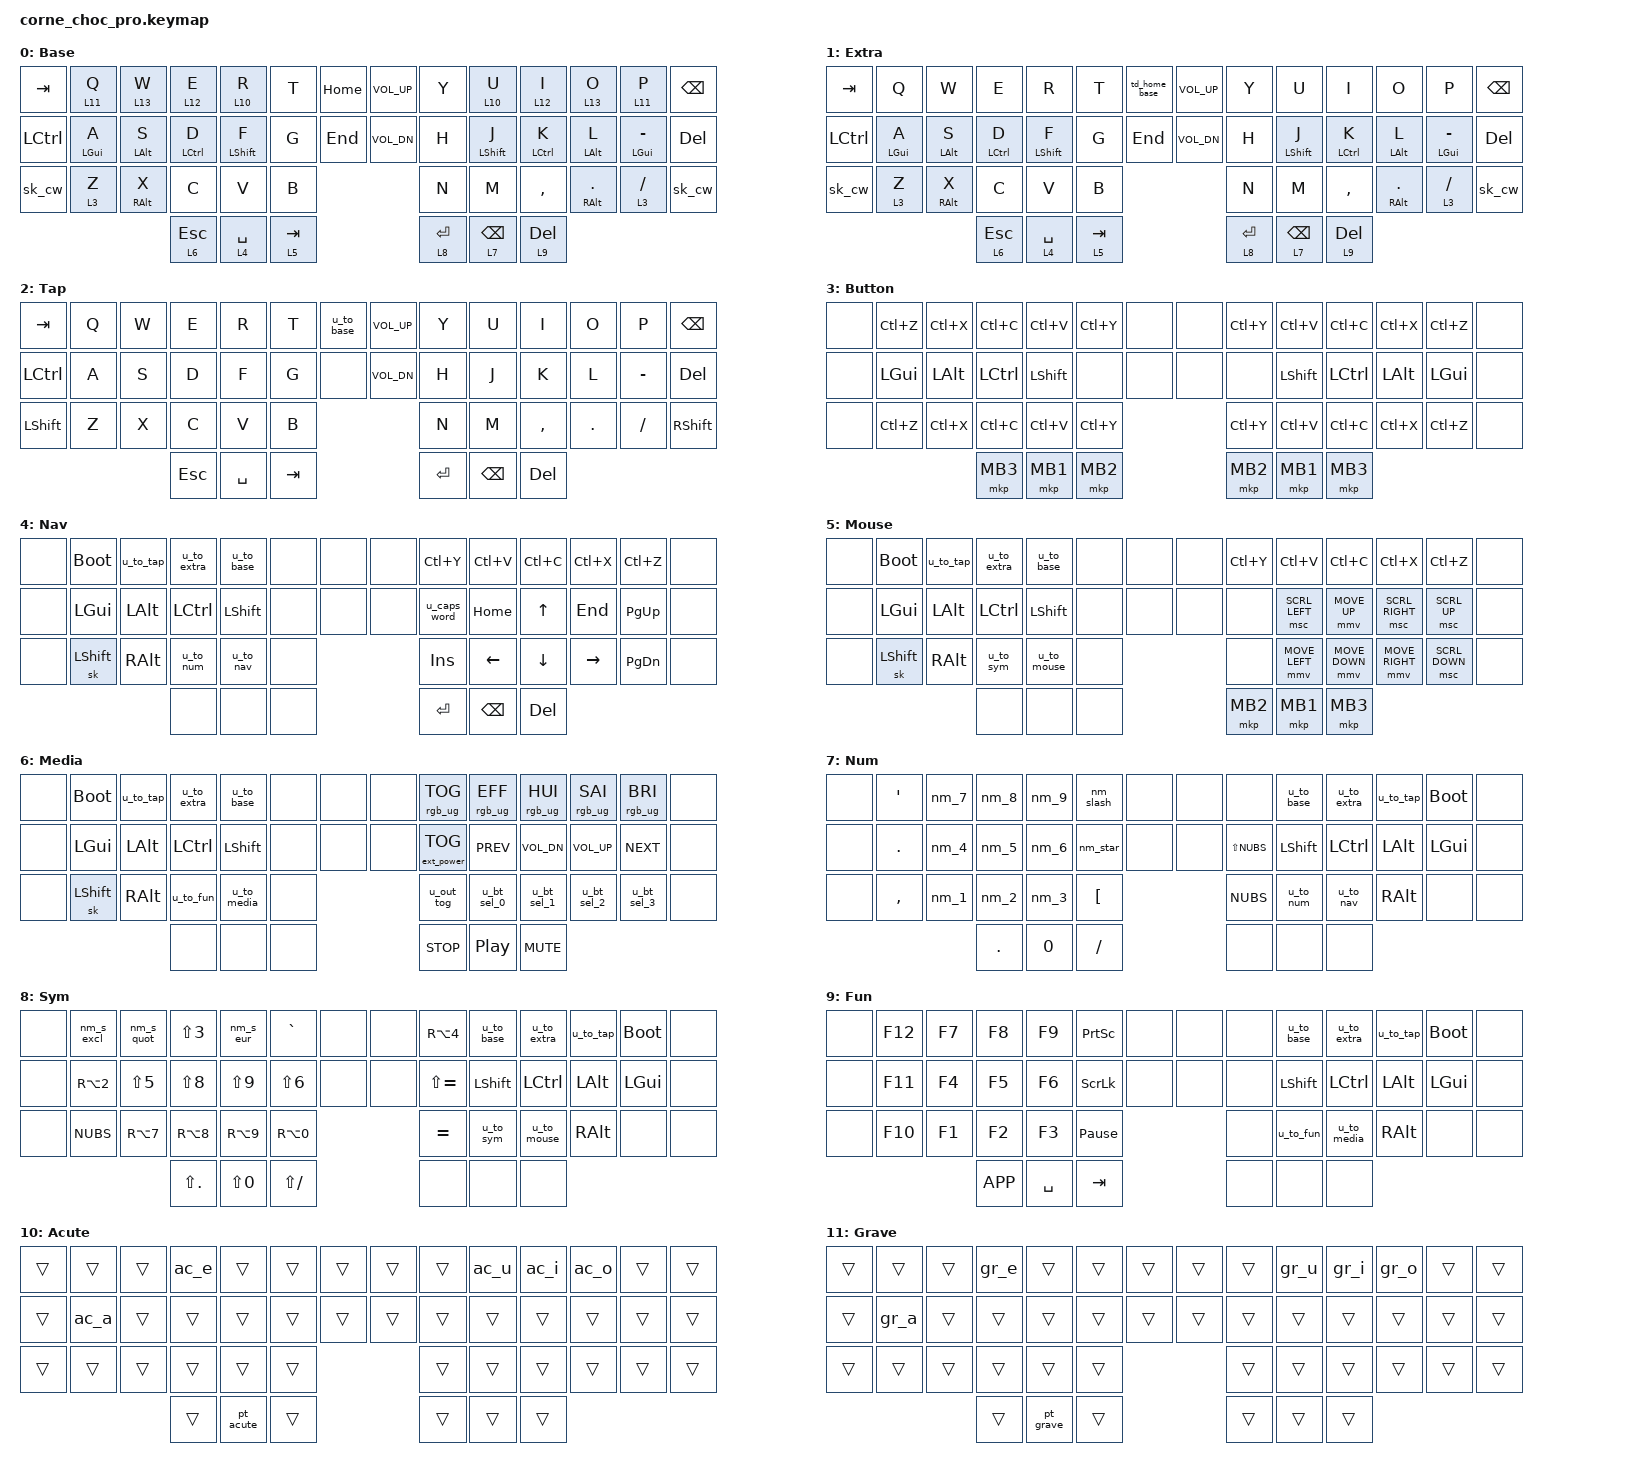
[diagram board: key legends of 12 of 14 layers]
/*
 * Miryoku layout for the Keebart Corne Choc Pro BT (42 keys + 4 centre keys).
 *
 * Expanded by hand from Keebart/miryoku_zmk (manna-harbour/miryoku_zmk) so the
 * ZMK Keymap Editor can read and edit it: every layer is written out as plain
 * bindings and Miryoku's behaviours are plain devicetree nodes, no C-preprocessor
 * layer macros.
 *
 * Options used: alphas = QWERTY, tap layer = QWERTY, extra layer = QWERTY,
 * everything else Miryoku default (home-row navigation on the right hand,
 * Num / Sym / Fun on the left, CUA clipboard keys, no flipped layers).
 *
 * Layer order: 0 Base, 1 Extra, 2 Tap, 3 Button, 4 Nav, 5 Mouse, 6 Media,
 *              7 Num, 8 Sym, 9 Fun, 10 Acute, 11 Grave, 12 Tilde, 13 Circ.
 *              Layer numbers are used in the bindings.
 *
 * Miryoku uses the 36 core keys; the 4 centre keys are &none and free for your
 * own bindings.
 *
 * PORTUGUESE (PORTUGAL) LAYOUT: every character on the Num and Sym layers is sent
 * as the key sequence that prints it on the Windows Portuguese layout (AltGr for
 * [ ] { } @ EUR, Shift for ! " # $ % & ( ) = : ; _ ?, dead key + Space for ` ^ ~ ´ ¨).
 * On the alpha layers the bottom-right key is the physical Portuguese key: -
 * (Shift _); the right pinky sends ' (Shift ?).
 *
 * NUM (hold Backspace): numpad block 7 8 9 / 4 5 6 / 1 2 3, with . , º on the pinky
 * column, / * + on the extra index column, 0 and - on the thumbs, > < on the right
 * hand.  Shift gives the small character of each key: 7 ^  8 ~  9 ´  / `  * ¨  4 %
 * 5 (  6 )  1 EUR  2 $  3 £  . :  , ;  0 =  - _  º ª.
 * SYM (hold Enter): rows  ! " # EUR backslash / @ % ( ) & / < { [ ] }, thumbs : = _ ,
 * § » « on the right hand (Y H N).  Shift: ! ?  " '  EUR $  backslash |  < >.
 * NAV / MOUSE: inverted-T cluster on the right hand (Home Up End PgUp / Left Down
 * Right PgDn, and Scroll L / Mouse Up / Scroll R / Scroll Up / Mouse L, D, R /
 * Scroll Down); the left-hand bottom pinky key is a one-shot Shift (also on Media).
 *
 * CENTRE KEYS (Base and Extra): left pair = Home / End, right pair = Volume Up / Volume Down.
 *
 * OUTER COLUMNS (Base and Extra):  Tab / Ctrl / Shift  |  Backspace / Del / Shift.
 * Shift is one-shot (tap, then the next key is capital); tap it again while it
 * is active for Caps Word; hold it for normal Shift.  The Tap (gaming) layer has
 * plain Shift keys.
 *
 * ACCENTS (Windows, Portuguese (Portugal) keyboard layout)
 * Hold a top-row key on the Base layer and tap a vowel to get an accented one:
 *     hold R or U  + vowel -> acute      (a e i o u)
 *     hold E or I  + vowel -> tilde      (a o, and n for ñ)
 *     hold W or O  + vowel -> circumflex (a e i o u)
 *     hold Q or P  + vowel -> grave      (a e i o u)
 *     tap C + V together   -> Ç          (Shift gives Ç)
 * They send the dead key of the PT-PT layout, then the vowel; Shift is handled so
 * capital letters work.  The Extra layer is plain Miryoku QWERTY without accents.
 * Dead keys used (physical keys): acute = key right of "+", tilde = key left of
 * Enter, grave / circumflex = the same keys with Shift, Ç = key right of "L".
 */

/* Miryoku mouse tuning; must come before pointing.h (its defaults are #ifndef) */
#define ZMK_POINTING_DEFAULT_MOVE_VAL 1250
#define ZMK_POINTING_DEFAULT_SCRL_VAL 100

#include <behaviors.dtsi>
#include <behaviors/mouse_keys.dtsi>
#include <dt-bindings/zmk/keys.h>
#include <dt-bindings/zmk/bt.h>
#include <dt-bindings/zmk/rgb.h>
#include <dt-bindings/zmk/outputs.h>
#include <dt-bindings/zmk/ext_power.h>
#include <dt-bindings/zmk/pointing.h>

/ {
    chosen {
        zmk,physical-layout = &default_layout;
    };
};
/ {
    keymap {
        compatible = "zmk,keymap";

        base_layer {
            display-name = "Base";
            bindings = <
                &kp TAB   &acc_lt 11 Q &acc_lt 13 W &acc_lt 12 E  &acc_lt 10 R  &kp T       &kp HOME &kp C_VOL_UP &kp Y       &acc_lt 10 U  &acc_lt 12 I  &acc_lt 13 O   &acc_lt 11 P     &kp BSPC
                &kp LCTRL &u_mt LGUI A &u_mt LALT S &u_mt LCTRL D &u_mt LSHFT F &kp G       &kp END  &kp C_VOL_DN &kp H       &u_mt LSHFT J &u_mt LCTRL K &u_mt LALT L   &u_mt LGUI MINUS &kp DEL
                &sk_cw    &u_lt 3 Z    &u_mt RALT X &kp C         &kp V         &kp B                             &kp N       &kp M         &kp COMMA     &u_mt RALT DOT &u_lt 3 SLASH    &sk_cw
                                                    &u_lt 6 ESC   &u_lt 4 SPACE &u_lt 5 TAB                       &u_lt 8 RET &u_lt 7 BSPC  &u_lt 9 DEL
            >;
        };

        extra_layer {
            display-name = "Extra";
            bindings = <
                &kp TAB   &kp Q        &kp W        &kp E         &kp R         &kp T       &td_home_base &kp C_VOL_UP &kp Y       &kp U         &kp I         &kp O          &kp P            &kp BSPC
                &kp LCTRL &u_mt LGUI A &u_mt LALT S &u_mt LCTRL D &u_mt LSHFT F &kp G       &kp END       &kp C_VOL_DN &kp H       &u_mt LSHFT J &u_mt LCTRL K &u_mt LALT L   &u_mt LGUI MINUS &kp DEL
                &sk_cw    &u_lt 3 Z    &u_mt RALT X &kp C         &kp V         &kp B                                  &kp N       &kp M         &kp COMMA     &u_mt RALT DOT &u_lt 3 SLASH    &sk_cw
                                                    &u_lt 6 ESC   &u_lt 4 SPACE &u_lt 5 TAB                            &u_lt 8 RET &u_lt 7 BSPC  &u_lt 9 DEL
            >;
        };

        tap_layer {
            display-name = "Tap";
            bindings = <
                &kp TAB   &kp Q &kp W &kp E   &kp R     &kp T   &u_to_base &kp C_VOL_UP &kp Y   &kp U    &kp I     &kp O   &kp P     &kp BSPC
                &kp LCTRL &kp A &kp S &kp D   &kp F     &kp G   &none      &kp C_VOL_DN &kp H   &kp J    &kp K     &kp L   &kp MINUS &kp DEL
                &kp LSHFT &kp Z &kp X &kp C   &kp V     &kp B                           &kp N   &kp M    &kp COMMA &kp DOT &kp SLASH &kp RSHFT
                                      &kp ESC &kp SPACE &kp TAB                         &kp RET &kp BSPC &kp DEL
            >;
        };

        button_layer {
            display-name = "Button";
            bindings = <
                &none &kp LC(Z) &kp LC(X) &kp LC(C) &kp LC(V) &kp LC(Y) &none &none &kp LC(Y) &kp LC(V) &kp LC(C) &kp LC(X) &kp LC(Z) &none
                &none &kp LGUI  &kp LALT  &kp LCTRL &kp LSHFT &none     &none &none &none     &kp LSHFT &kp LCTRL &kp LALT  &kp LGUI  &none
                &none &kp LC(Z) &kp LC(X) &kp LC(C) &kp LC(V) &kp LC(Y)             &kp LC(Y) &kp LC(V) &kp LC(C) &kp LC(X) &kp LC(Z) &none
                                          &mkp MB3  &mkp MB1  &mkp MB2              &mkp MB2  &mkp MB1  &mkp MB3
            >;
        };

        nav_layer {
            display-name = "Nav";
            bindings = <
                &none &bootloader &u_to_tap &u_to_extra &u_to_base &none &none &none &kp LC(Y)    &kp LC(V) &kp LC(C) &kp LC(X) &kp LC(Z) &none
                &none &kp LGUI    &kp LALT  &kp LCTRL   &kp LSHFT  &none &none &none &u_caps_word &kp HOME  &kp UP    &kp END   &kp PG_UP &none
                &none &sk LSHFT   &kp RALT  &u_to_num   &u_to_nav  &none             &kp INS      &kp LEFT  &kp DOWN  &kp RIGHT &kp PG_DN &none
                                            &none       &none      &none             &kp RET      &kp BSPC  &kp DEL
            >;
        };

        mouse_layer {
            display-name = "Mouse";
            bindings = <
                &none &bootloader &u_to_tap &u_to_extra &u_to_base  &none &none &none &kp LC(Y) &kp LC(V)      &kp LC(C)      &kp LC(X)       &kp LC(Z)      &none
                &none &kp LGUI    &kp LALT  &kp LCTRL   &kp LSHFT   &none &none &none &none     &msc SCRL_LEFT &mmv MOVE_UP   &msc SCRL_RIGHT &msc SCRL_UP   &none
                &none &sk LSHFT   &kp RALT  &u_to_sym   &u_to_mouse &none             &none     &mmv MOVE_LEFT &mmv MOVE_DOWN &mmv MOVE_RIGHT &msc SCRL_DOWN &none
                                            &none       &none       &none             &mkp MB2  &mkp MB1       &mkp MB3
            >;
        };

        media_layer {
            display-name = "Media";
            bindings = <
                &none &bootloader &u_to_tap &u_to_extra &u_to_base  &none &none &none &rgb_ug RGB_TOG   &rgb_ug RGB_EFF &rgb_ug RGB_HUI &rgb_ug RGB_SAI &rgb_ug RGB_BRI &none
                &none &kp LGUI    &kp LALT  &kp LCTRL   &kp LSHFT   &none &none &none &ext_power EP_TOG &kp C_PREV      &kp C_VOL_DN    &kp C_VOL_UP    &kp C_NEXT      &none
                &none &sk LSHFT   &kp RALT  &u_to_fun   &u_to_media &none             &u_out_tog        &u_bt_sel_0     &u_bt_sel_1     &u_bt_sel_2     &u_bt_sel_3     &none
                                            &none       &none       &none             &kp C_STOP        &kp C_PP        &kp C_MUTE
            >;
        };

        num_layer {
            display-name = "Num";
            bindings = <
                &none &kp SQT   &nm_7 &nm_8   &nm_9  &nm_slash &none &none &none        &u_to_base &u_to_extra &u_to_tap &bootloader &none
                &none &kp DOT   &nm_4 &nm_5   &nm_6  &nm_star  &none &none &kp LS(NUBS) &kp LSHFT  &kp LCTRL   &kp LALT  &kp LGUI    &none
                &none &kp COMMA &nm_1 &nm_2   &nm_3  &kp LBKT              &kp NUBS     &u_to_num  &u_to_nav   &kp RALT  &none       &none
                                      &kp DOT &kp N0 &kp SLASH             &none        &none      &none
            >;
        };

        sym_layer {
            display-name = "Sym";
            bindings = <
                &none &nm_s_excl &nm_s_quot &kp LS(N3)  &nm_s_eur  &kp GRAVE     &none &none &kp RA(N4)    &u_to_base &u_to_extra &u_to_tap &bootloader &none
                &none &kp RA(N2) &kp LS(N5) &kp LS(N8)  &kp LS(N9) &kp LS(N6)    &none &none &kp LS(EQUAL) &kp LSHFT  &kp LCTRL   &kp LALT  &kp LGUI    &none
                &none &kp NUBS   &kp RA(N7) &kp RA(N8)  &kp RA(N9) &kp RA(N0)                &kp EQUAL     &u_to_sym  &u_to_mouse &kp RALT  &none       &none
                                            &kp LS(DOT) &kp LS(N0) &kp LS(SLASH)             &none         &none      &none
            >;
        };

        fun_layer {
            display-name = "Fun";
            bindings = <
                &none &kp F12 &kp F7 &kp F8    &kp F9    &kp PSCRN       &none &none &none &u_to_base &u_to_extra &u_to_tap &bootloader &none
                &none &kp F11 &kp F4 &kp F5    &kp F6    &kp SLCK        &none &none &none &kp LSHFT  &kp LCTRL   &kp LALT  &kp LGUI    &none
                &none &kp F10 &kp F1 &kp F2    &kp F3    &kp PAUSE_BREAK             &none &u_to_fun  &u_to_media &kp RALT  &none       &none
                                     &kp K_APP &kp SPACE &kp TAB                     &none &none      &none
            >;
        };

        acute_layer {
            display-name = "Acute";
            bindings = <
                &trans &trans &trans &ac_e  &trans    &trans &trans &trans &trans &ac_u  &ac_i  &ac_o  &trans &trans
                &trans &ac_a  &trans &trans &trans    &trans &trans &trans &trans &trans &trans &trans &trans &trans
                &trans &trans &trans &trans &trans    &trans               &trans &trans &trans &trans &trans &trans
                                     &trans &pt_acute &trans               &trans &trans &trans
            >;
        };

        grave_layer {
            display-name = "Grave";
            bindings = <
                &trans &trans &trans &gr_e  &trans    &trans &trans &trans &trans &gr_u  &gr_i  &gr_o  &trans &trans
                &trans &gr_a  &trans &trans &trans    &trans &trans &trans &trans &trans &trans &trans &trans &trans
                &trans &trans &trans &trans &trans    &trans               &trans &trans &trans &trans &trans &trans
                                     &trans &pt_grave &trans               &trans &trans &trans
            >;
        };

        tilde_layer {
            display-name = "Tilde";
            bindings = <
                &trans &trans &trans &trans &trans    &trans &trans &trans &trans &trans &trans &ti_o  &trans &trans
                &trans &ti_a  &trans &trans &trans    &trans &trans &trans &trans &trans &trans &trans &trans &trans
                &trans &trans &trans &trans &trans    &trans               &ti_n  &trans &trans &trans &trans &trans
                                     &trans &pt_tilde &trans               &trans &trans &trans
            >;
        };

        circ_layer {
            display-name = "Circ";
            bindings = <
                &trans &trans &trans &ci_e  &trans    &trans &trans &trans &trans &ci_u  &ci_i  &ci_o  &trans &trans
                &trans &ci_a  &trans &trans &trans    &trans &trans &trans &trans &trans &trans &trans &trans &trans
                &trans &trans &trans &trans &trans    &trans               &trans &trans &trans &trans &trans &trans
                                     &trans &pt_caret &trans               &trans &trans &trans
            >;
        };
    };
};

/* ---- Miryoku behaviours ------------------------------------------------- */

/ {
    behaviors {
        /* home-row mod-tap: &u_mt <modifier> <key> */
        u_mt: u_mt {
            compatible = "zmk,behavior-hold-tap";
            #binding-cells = <2>;
            tapping-term-ms = <200>;
            flavor = "tap-preferred";
            bindings = <&kp>, <&kp>;
        };

        /* layer-tap: &u_lt <layer> <key> */
        u_lt: u_lt {
            compatible = "zmk,behavior-hold-tap";
            #binding-cells = <2>;
            tapping-term-ms = <200>;
            flavor = "tap-preferred";
            bindings = <&mo>, <&kp>;
        };

        /* accent layer-tap: &acc_lt <layer> <key>.  Same timing as Miryoku's
           home-row keys; quick-tap keeps repeated letters and key repeat working */
        acc_lt: acc_lt {
            compatible = "zmk,behavior-hold-tap";
            #binding-cells = <2>;
            tapping-term-ms = <200>;
            quick-tap-ms = <175>;
            flavor = "tap-preferred";
            bindings = <&mo>, <&kp>;
        };

        /* double-tap guards: a single tap does nothing, a double tap switches layer */
        u_to_base: u_to_base {
            compatible = "zmk,behavior-tap-dance";
            #binding-cells = <0>;
            tapping-term-ms = <200>;
            bindings = <&none>, <&to 0>;
        };
        u_to_extra: u_to_extra {
            compatible = "zmk,behavior-tap-dance";
            #binding-cells = <0>;
            tapping-term-ms = <200>;
            bindings = <&none>, <&to 1>;
        };
        u_to_tap: u_to_tap {
            compatible = "zmk,behavior-tap-dance";
            #binding-cells = <0>;
            tapping-term-ms = <200>;
            bindings = <&none>, <&to 2>;
        };
        u_to_button: u_to_button {
            compatible = "zmk,behavior-tap-dance";
            #binding-cells = <0>;
            tapping-term-ms = <200>;
            bindings = <&none>, <&to 3>;
        };
        u_to_nav: u_to_nav {
            compatible = "zmk,behavior-tap-dance";
            #binding-cells = <0>;
            tapping-term-ms = <200>;
            bindings = <&none>, <&to 4>;
        };
        u_to_mouse: u_to_mouse {
            compatible = "zmk,behavior-tap-dance";
            #binding-cells = <0>;
            tapping-term-ms = <200>;
            bindings = <&none>, <&to 5>;
        };
        u_to_media: u_to_media {
            compatible = "zmk,behavior-tap-dance";
            #binding-cells = <0>;
            tapping-term-ms = <200>;
            bindings = <&none>, <&to 6>;
        };
        u_to_num: u_to_num {
            compatible = "zmk,behavior-tap-dance";
            #binding-cells = <0>;
            tapping-term-ms = <200>;
            bindings = <&none>, <&to 7>;
        };
        u_to_sym: u_to_sym {
            compatible = "zmk,behavior-tap-dance";
            #binding-cells = <0>;
            tapping-term-ms = <200>;
            bindings = <&none>, <&to 8>;
        };
        u_to_fun: u_to_fun {
            compatible = "zmk,behavior-tap-dance";
            #binding-cells = <0>;
            tapping-term-ms = <200>;
            bindings = <&none>, <&to 9>;
        };
        /* Extra layer, top-left centre: tap = Home, double-tap = back to Base */
        td_home_base: td_home_base {
            compatible = "zmk,behavior-tap-dance";
            #binding-cells = <0>;
            tapping-term-ms = <200>;
            bindings = <&kp HOME>, <&to 0>;
        };

        /* shift = alternate function */
        u_bt_sel_0: u_bt_sel_0 {
            compatible = "zmk,behavior-mod-morph";
            #binding-cells = <0>;
            bindings = <&bt BT_SEL 0>, <&u_bt_sel_0_clr>;
            mods = <(MOD_LSFT|MOD_RSFT)>;
        };
        u_bt_sel_1: u_bt_sel_1 {
            compatible = "zmk,behavior-mod-morph";
            #binding-cells = <0>;
            bindings = <&bt BT_SEL 1>, <&u_bt_sel_1_clr>;
            mods = <(MOD_LSFT|MOD_RSFT)>;
        };
        u_bt_sel_2: u_bt_sel_2 {
            compatible = "zmk,behavior-mod-morph";
            #binding-cells = <0>;
            bindings = <&bt BT_SEL 2>, <&u_bt_sel_2_clr>;
            mods = <(MOD_LSFT|MOD_RSFT)>;
        };
        u_bt_sel_3: u_bt_sel_3 {
            compatible = "zmk,behavior-mod-morph";
            #binding-cells = <0>;
            bindings = <&bt BT_SEL 3>, <&u_bt_sel_3_clr>;
            mods = <(MOD_LSFT|MOD_RSFT)>;
        };
        u_out_tog: u_out_tog {
            compatible = "zmk,behavior-mod-morph";
            #binding-cells = <0>;
            bindings = <&out OUT_TOG>, <&out OUT_USB>;
            mods = <(MOD_LSFT|MOD_RSFT)>;
        };
        u_caps_word: u_caps_word {
            compatible = "zmk,behavior-mod-morph";
            #binding-cells = <0>;
            bindings = <&caps_word>, <&kp CAPS>;
            mods = <(MOD_LSFT|MOD_RSFT)>;
        };

        /* Shift: tap = one-shot Shift, tap again (while it is active) = Caps Word,
           hold = normal Shift */
        sk_cw: sk_cw {
            compatible = "zmk,behavior-mod-morph";
            #binding-cells = <0>;
            bindings = <&sk LSHFT>, <&caps_word>;
            mods = <(MOD_LSFT|MOD_RSFT)>;
        };

        /* accented vowels: Shift held = capital letter */
        ac_a: ac_a {
            compatible = "zmk,behavior-mod-morph";
            #binding-cells = <0>;
            bindings = <&ac_a_l>, <&ac_a_u>;
            mods = <(MOD_LSFT|MOD_RSFT)>;
        };
        ac_e: ac_e {
            compatible = "zmk,behavior-mod-morph";
            #binding-cells = <0>;
            bindings = <&ac_e_l>, <&ac_e_u>;
            mods = <(MOD_LSFT|MOD_RSFT)>;
        };
        ac_i: ac_i {
            compatible = "zmk,behavior-mod-morph";
            #binding-cells = <0>;
            bindings = <&ac_i_l>, <&ac_i_u>;
            mods = <(MOD_LSFT|MOD_RSFT)>;
        };
        ac_o: ac_o {
            compatible = "zmk,behavior-mod-morph";
            #binding-cells = <0>;
            bindings = <&ac_o_l>, <&ac_o_u>;
            mods = <(MOD_LSFT|MOD_RSFT)>;
        };
        ac_u: ac_u {
            compatible = "zmk,behavior-mod-morph";
            #binding-cells = <0>;
            bindings = <&ac_u_l>, <&ac_u_u>;
            mods = <(MOD_LSFT|MOD_RSFT)>;
        };
        gr_a: gr_a {
            compatible = "zmk,behavior-mod-morph";
            #binding-cells = <0>;
            bindings = <&gr_a_l>, <&gr_a_u>;
            mods = <(MOD_LSFT|MOD_RSFT)>;
        };
        gr_e: gr_e {
            compatible = "zmk,behavior-mod-morph";
            #binding-cells = <0>;
            bindings = <&gr_e_l>, <&gr_e_u>;
            mods = <(MOD_LSFT|MOD_RSFT)>;
        };
        gr_i: gr_i {
            compatible = "zmk,behavior-mod-morph";
            #binding-cells = <0>;
            bindings = <&gr_i_l>, <&gr_i_u>;
            mods = <(MOD_LSFT|MOD_RSFT)>;
        };
        gr_o: gr_o {
            compatible = "zmk,behavior-mod-morph";
            #binding-cells = <0>;
            bindings = <&gr_o_l>, <&gr_o_u>;
            mods = <(MOD_LSFT|MOD_RSFT)>;
        };
        gr_u: gr_u {
            compatible = "zmk,behavior-mod-morph";
            #binding-cells = <0>;
            bindings = <&gr_u_l>, <&gr_u_u>;
            mods = <(MOD_LSFT|MOD_RSFT)>;
        };
        ti_a: ti_a {
            compatible = "zmk,behavior-mod-morph";
            #binding-cells = <0>;
            bindings = <&ti_a_l>, <&ti_a_u>;
            mods = <(MOD_LSFT|MOD_RSFT)>;
        };
        ti_o: ti_o {
            compatible = "zmk,behavior-mod-morph";
            #binding-cells = <0>;
            bindings = <&ti_o_l>, <&ti_o_u>;
            mods = <(MOD_LSFT|MOD_RSFT)>;
        };
        ti_n: ti_n {
            compatible = "zmk,behavior-mod-morph";
            #binding-cells = <0>;
            bindings = <&ti_n_l>, <&ti_n_u>;
            mods = <(MOD_LSFT|MOD_RSFT)>;
        };
        ci_a: ci_a {
            compatible = "zmk,behavior-mod-morph";
            #binding-cells = <0>;
            bindings = <&ci_a_l>, <&ci_a_u>;
            mods = <(MOD_LSFT|MOD_RSFT)>;
        };
        ci_e: ci_e {
            compatible = "zmk,behavior-mod-morph";
            #binding-cells = <0>;
            bindings = <&ci_e_l>, <&ci_e_u>;
            mods = <(MOD_LSFT|MOD_RSFT)>;
        };
        ci_i: ci_i {
            compatible = "zmk,behavior-mod-morph";
            #binding-cells = <0>;
            bindings = <&ci_i_l>, <&ci_i_u>;
            mods = <(MOD_LSFT|MOD_RSFT)>;
        };
        ci_o: ci_o {
            compatible = "zmk,behavior-mod-morph";
            #binding-cells = <0>;
            bindings = <&ci_o_l>, <&ci_o_u>;
            mods = <(MOD_LSFT|MOD_RSFT)>;
        };
        ci_u: ci_u {
            compatible = "zmk,behavior-mod-morph";
            #binding-cells = <0>;
            bindings = <&ci_u_l>, <&ci_u_u>;
            mods = <(MOD_LSFT|MOD_RSFT)>;
        };

        /* Num / Sym keys: Shift gives the small character of the layout image */
        nm_7: nm_7 {
            compatible = "zmk,behavior-mod-morph";
            #binding-cells = <0>;
            bindings = <&kp N7>, <&pt_caret>;
            mods = <(MOD_LSFT|MOD_RSFT)>;
        };
        nm_8: nm_8 {
            compatible = "zmk,behavior-mod-morph";
            #binding-cells = <0>;
            bindings = <&kp N8>, <&pt_tilde>;
            mods = <(MOD_LSFT|MOD_RSFT)>;
        };
        nm_9: nm_9 {
            compatible = "zmk,behavior-mod-morph";
            #binding-cells = <0>;
            bindings = <&kp N9>, <&pt_acute>;
            mods = <(MOD_LSFT|MOD_RSFT)>;
        };
        nm_slash: nm_slash {
            compatible = "zmk,behavior-mod-morph";
            #binding-cells = <0>;
            bindings = <&kp LS(N7)>, <&pt_grave>;
            mods = <(MOD_LSFT|MOD_RSFT)>;
        };
        nm_star: nm_star {
            compatible = "zmk,behavior-mod-morph";
            #binding-cells = <0>;
            bindings = <&kp LS(LBKT)>, <&pt_trema>;
            mods = <(MOD_LSFT|MOD_RSFT)>;
        };
        nm_4: nm_4 {
            compatible = "zmk,behavior-mod-morph";
            #binding-cells = <0>;
            bindings = <&kp N4>, <&kp LS(N5)>;
            mods = <(MOD_LSFT|MOD_RSFT)>;
        };
        nm_5: nm_5 {
            compatible = "zmk,behavior-mod-morph";
            #binding-cells = <0>;
            bindings = <&kp N5>, <&kp LS(N8)>;
            mods = <(MOD_LSFT|MOD_RSFT)>;
        };
        nm_6: nm_6 {
            compatible = "zmk,behavior-mod-morph";
            #binding-cells = <0>;
            bindings = <&kp N6>, <&kp LS(N9)>;
            mods = <(MOD_LSFT|MOD_RSFT)>;
        };
        nm_1: nm_1 {
            compatible = "zmk,behavior-mod-morph";
            #binding-cells = <0>;
            bindings = <&kp N1>, <&kp RA(N5)>;
            mods = <(MOD_LSFT|MOD_RSFT)>;
        };
        nm_2: nm_2 {
            compatible = "zmk,behavior-mod-morph";
            #binding-cells = <0>;
            bindings = <&kp N2>, <&kp LS(N4)>;
            mods = <(MOD_LSFT|MOD_RSFT)>;
        };
        nm_3: nm_3 {
            compatible = "zmk,behavior-mod-morph";
            #binding-cells = <0>;
            bindings = <&kp N3>, <&kp RA(N3)>;
            mods = <(MOD_LSFT|MOD_RSFT)>;
        };
        nm_s_excl: nm_s_excl {
            compatible = "zmk,behavior-mod-morph";
            #binding-cells = <0>;
            bindings = <&kp LS(N1)>, <&kp LS(MINUS)>;
            mods = <(MOD_LSFT|MOD_RSFT)>;
        };
        nm_s_quot: nm_s_quot {
            compatible = "zmk,behavior-mod-morph";
            #binding-cells = <0>;
            bindings = <&kp LS(N2)>, <&kp MINUS>;
            mods = <(MOD_LSFT|MOD_RSFT)>;
        };
        nm_s_eur: nm_s_eur {
            compatible = "zmk,behavior-mod-morph";
            #binding-cells = <0>;
            bindings = <&kp RA(N5)>, <&kp LS(N4)>;
            mods = <(MOD_LSFT|MOD_RSFT)>;
        };
    };

    macros {
        /* shifted Bluetooth select = select profile, then clear it */
        u_bt_sel_0_clr: u_bt_sel_0_clr {
            compatible = "zmk,behavior-macro";
            #binding-cells = <0>;
            wait-ms = <0>;
            bindings = <&bt BT_SEL 0 &bt BT_CLR>;
        };
        u_bt_sel_1_clr: u_bt_sel_1_clr {
            compatible = "zmk,behavior-macro";
            #binding-cells = <0>;
            wait-ms = <0>;
            bindings = <&bt BT_SEL 1 &bt BT_CLR>;
        };
        u_bt_sel_2_clr: u_bt_sel_2_clr {
            compatible = "zmk,behavior-macro";
            #binding-cells = <0>;
            wait-ms = <0>;
            bindings = <&bt BT_SEL 2 &bt BT_CLR>;
        };
        u_bt_sel_3_clr: u_bt_sel_3_clr {
            compatible = "zmk,behavior-macro";
            #binding-cells = <0>;
            wait-ms = <0>;
            bindings = <&bt BT_SEL 3 &bt BT_CLR>;
        };

        /* stand-alone ´ ` ^ ~ on the Portuguese layout: dead key, then Space */
        pt_acute: pt_acute {
            compatible = "zmk,behavior-macro";
            #binding-cells = <0>;
            wait-ms = <10>;
            tap-ms = <20>;
            bindings = <&macro_tap &kp RBKT &kp SPACE>;
        };
        pt_trema: pt_trema {
            compatible = "zmk,behavior-macro";
            #binding-cells = <0>;
            wait-ms = <10>;
            tap-ms = <20>;
            bindings = <&macro_tap &kp RA(LBKT) &kp SPACE>;
        };
        pt_grave: pt_grave {
            compatible = "zmk,behavior-macro";
            #binding-cells = <0>;
            wait-ms = <10>;
            tap-ms = <20>;
            bindings = <&macro_tap &kp LS(RBKT) &kp SPACE>;
        };
        pt_caret: pt_caret {
            compatible = "zmk,behavior-macro";
            #binding-cells = <0>;
            wait-ms = <10>;
            tap-ms = <20>;
            bindings = <&macro_tap &kp LS(NUHS) &kp SPACE>;
        };
        pt_tilde: pt_tilde {
            compatible = "zmk,behavior-macro";
            #binding-cells = <0>;
            wait-ms = <10>;
            tap-ms = <20>;
            bindings = <&macro_tap &kp NUHS &kp SPACE>;
        };

        /* dead key, then the vowel (_l = lower case, _u = upper case) */
        ac_a_l: ac_a_l {
            compatible = "zmk,behavior-macro";
            #binding-cells = <0>;
            wait-ms = <10>;
            tap-ms = <20>;
            bindings = <&macro_tap &kp RBKT &kp A>;
        };
        ac_a_u: ac_a_u {
            compatible = "zmk,behavior-macro";
            #binding-cells = <0>;
            wait-ms = <10>;
            tap-ms = <20>;
            bindings = <&macro_tap &kp RBKT &kp LS(A)>;
        };
        ac_e_l: ac_e_l {
            compatible = "zmk,behavior-macro";
            #binding-cells = <0>;
            wait-ms = <10>;
            tap-ms = <20>;
            bindings = <&macro_tap &kp RBKT &kp E>;
        };
        ac_e_u: ac_e_u {
            compatible = "zmk,behavior-macro";
            #binding-cells = <0>;
            wait-ms = <10>;
            tap-ms = <20>;
            bindings = <&macro_tap &kp RBKT &kp LS(E)>;
        };
        ac_i_l: ac_i_l {
            compatible = "zmk,behavior-macro";
            #binding-cells = <0>;
            wait-ms = <10>;
            tap-ms = <20>;
            bindings = <&macro_tap &kp RBKT &kp I>;
        };
        ac_i_u: ac_i_u {
            compatible = "zmk,behavior-macro";
            #binding-cells = <0>;
            wait-ms = <10>;
            tap-ms = <20>;
            bindings = <&macro_tap &kp RBKT &kp LS(I)>;
        };
        ac_o_l: ac_o_l {
            compatible = "zmk,behavior-macro";
            #binding-cells = <0>;
            wait-ms = <10>;
            tap-ms = <20>;
            bindings = <&macro_tap &kp RBKT &kp O>;
        };
        ac_o_u: ac_o_u {
            compatible = "zmk,behavior-macro";
            #binding-cells = <0>;
            wait-ms = <10>;
            tap-ms = <20>;
            bindings = <&macro_tap &kp RBKT &kp LS(O)>;
        };
        ac_u_l: ac_u_l {
            compatible = "zmk,behavior-macro";
            #binding-cells = <0>;
            wait-ms = <10>;
            tap-ms = <20>;
            bindings = <&macro_tap &kp RBKT &kp U>;
        };
        ac_u_u: ac_u_u {
            compatible = "zmk,behavior-macro";
            #binding-cells = <0>;
            wait-ms = <10>;
            tap-ms = <20>;
            bindings = <&macro_tap &kp RBKT &kp LS(U)>;
        };
        gr_a_l: gr_a_l {
            compatible = "zmk,behavior-macro";
            #binding-cells = <0>;
            wait-ms = <10>;
            tap-ms = <20>;
            bindings = <&macro_tap &kp LS(RBKT) &kp A>;
        };
        gr_a_u: gr_a_u {
            compatible = "zmk,behavior-macro";
            #binding-cells = <0>;
            wait-ms = <10>;
            tap-ms = <20>;
            bindings = <&macro_tap &kp LS(RBKT) &kp LS(A)>;
        };
        gr_e_l: gr_e_l {
            compatible = "zmk,behavior-macro";
            #binding-cells = <0>;
            wait-ms = <10>;
            tap-ms = <20>;
            bindings = <&macro_tap &kp LS(RBKT) &kp E>;
        };
        gr_e_u: gr_e_u {
            compatible = "zmk,behavior-macro";
            #binding-cells = <0>;
            wait-ms = <10>;
            tap-ms = <20>;
            bindings = <&macro_tap &kp LS(RBKT) &kp LS(E)>;
        };
        gr_i_l: gr_i_l {
            compatible = "zmk,behavior-macro";
            #binding-cells = <0>;
            wait-ms = <10>;
            tap-ms = <20>;
            bindings = <&macro_tap &kp LS(RBKT) &kp I>;
        };
        gr_i_u: gr_i_u {
            compatible = "zmk,behavior-macro";
            #binding-cells = <0>;
            wait-ms = <10>;
            tap-ms = <20>;
            bindings = <&macro_tap &kp LS(RBKT) &kp LS(I)>;
        };
        gr_o_l: gr_o_l {
            compatible = "zmk,behavior-macro";
            #binding-cells = <0>;
            wait-ms = <10>;
            tap-ms = <20>;
            bindings = <&macro_tap &kp LS(RBKT) &kp O>;
        };
        gr_o_u: gr_o_u {
            compatible = "zmk,behavior-macro";
            #binding-cells = <0>;
            wait-ms = <10>;
            tap-ms = <20>;
            bindings = <&macro_tap &kp LS(RBKT) &kp LS(O)>;
        };
        gr_u_l: gr_u_l {
            compatible = "zmk,behavior-macro";
            #binding-cells = <0>;
            wait-ms = <10>;
            tap-ms = <20>;
            bindings = <&macro_tap &kp LS(RBKT) &kp U>;
        };
        gr_u_u: gr_u_u {
            compatible = "zmk,behavior-macro";
            #binding-cells = <0>;
            wait-ms = <10>;
            tap-ms = <20>;
            bindings = <&macro_tap &kp LS(RBKT) &kp LS(U)>;
        };
        ti_a_l: ti_a_l {
            compatible = "zmk,behavior-macro";
            #binding-cells = <0>;
            wait-ms = <10>;
            tap-ms = <20>;
            bindings = <&macro_tap &kp NUHS &kp A>;
        };
        ti_a_u: ti_a_u {
            compatible = "zmk,behavior-macro";
            #binding-cells = <0>;
            wait-ms = <10>;
            tap-ms = <20>;
            bindings = <&macro_tap &kp NUHS &kp LS(A)>;
        };
        ti_o_l: ti_o_l {
            compatible = "zmk,behavior-macro";
            #binding-cells = <0>;
            wait-ms = <10>;
            tap-ms = <20>;
            bindings = <&macro_tap &kp NUHS &kp O>;
        };
        ti_o_u: ti_o_u {
            compatible = "zmk,behavior-macro";
            #binding-cells = <0>;
            wait-ms = <10>;
            tap-ms = <20>;
            bindings = <&macro_tap &kp NUHS &kp LS(O)>;
        };
        ti_n_l: ti_n_l {
            compatible = "zmk,behavior-macro";
            #binding-cells = <0>;
            wait-ms = <10>;
            tap-ms = <20>;
            bindings = <&macro_tap &kp NUHS &kp N>;
        };
        ti_n_u: ti_n_u {
            compatible = "zmk,behavior-macro";
            #binding-cells = <0>;
            wait-ms = <10>;
            tap-ms = <20>;
            bindings = <&macro_tap &kp NUHS &kp LS(N)>;
        };
        ci_a_l: ci_a_l {
            compatible = "zmk,behavior-macro";
            #binding-cells = <0>;
            wait-ms = <10>;
            tap-ms = <20>;
            bindings = <&macro_tap &kp LS(NUHS) &kp A>;
        };
        ci_a_u: ci_a_u {
            compatible = "zmk,behavior-macro";
            #binding-cells = <0>;
            wait-ms = <10>;
            tap-ms = <20>;
            bindings = <&macro_tap &kp LS(NUHS) &kp LS(A)>;
        };
        ci_e_l: ci_e_l {
            compatible = "zmk,behavior-macro";
            #binding-cells = <0>;
            wait-ms = <10>;
            tap-ms = <20>;
            bindings = <&macro_tap &kp LS(NUHS) &kp E>;
        };
        ci_e_u: ci_e_u {
            compatible = "zmk,behavior-macro";
            #binding-cells = <0>;
            wait-ms = <10>;
            tap-ms = <20>;
            bindings = <&macro_tap &kp LS(NUHS) &kp LS(E)>;
        };
        ci_i_l: ci_i_l {
            compatible = "zmk,behavior-macro";
            #binding-cells = <0>;
            wait-ms = <10>;
            tap-ms = <20>;
            bindings = <&macro_tap &kp LS(NUHS) &kp I>;
        };
        ci_i_u: ci_i_u {
            compatible = "zmk,behavior-macro";
            #binding-cells = <0>;
            wait-ms = <10>;
            tap-ms = <20>;
            bindings = <&macro_tap &kp LS(NUHS) &kp LS(I)>;
        };
        ci_o_l: ci_o_l {
            compatible = "zmk,behavior-macro";
            #binding-cells = <0>;
            wait-ms = <10>;
            tap-ms = <20>;
            bindings = <&macro_tap &kp LS(NUHS) &kp O>;
        };
        ci_o_u: ci_o_u {
            compatible = "zmk,behavior-macro";
            #binding-cells = <0>;
            wait-ms = <10>;
            tap-ms = <20>;
            bindings = <&macro_tap &kp LS(NUHS) &kp LS(O)>;
        };
        ci_u_l: ci_u_l {
            compatible = "zmk,behavior-macro";
            #binding-cells = <0>;
            wait-ms = <10>;
            tap-ms = <20>;
            bindings = <&macro_tap &kp LS(NUHS) &kp U>;
        };
        ci_u_u: ci_u_u {
            compatible = "zmk,behavior-macro";
            #binding-cells = <0>;
            wait-ms = <10>;
            tap-ms = <20>;
            bindings = <&macro_tap &kp LS(NUHS) &kp LS(U)>;
        };
    };

    /* Ç: tap C and V together */
    combos {
        compatible = "zmk,combos";
        combo_cedilla {
            timeout-ms = <40>;
            key-positions = <31 32>;
            bindings = <&kp SEMI>;
            layers = <0>;
        };
    };
};

/* Miryoku mouse movement tuning */
&mmv {
    acceleration-exponent = <1>;
    time-to-max-speed-ms = <1500>;
    delay-ms = <0>;
};
